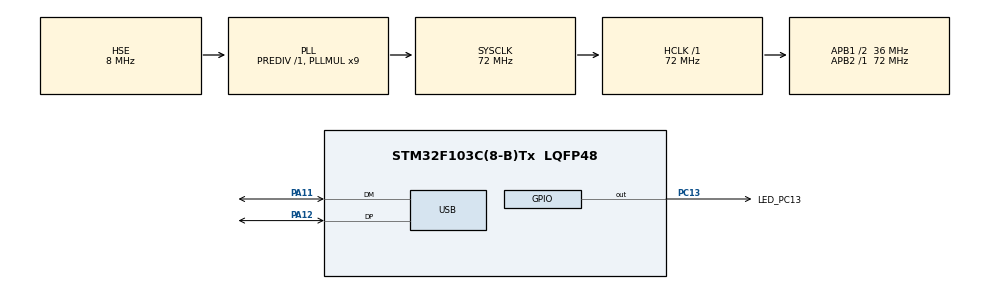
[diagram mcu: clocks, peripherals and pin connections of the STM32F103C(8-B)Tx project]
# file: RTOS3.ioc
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FREERTOS.BinarySemaphores01=myBinarySem01,Dynamic,NULL,Available
FREERTOS.Queues01=myQueue01,16,uint16_t,0,Dynamic,NULL,NULL
FREERTOS.Tasks01=defaultTask,0,128,StartDefaultTask,Default,NULL,Dynamic,NULL,NULL;LEDTask,-2,128,LEDFun,Default,NULL,Dynamic,NULL,NULL;USBFTask,-2,128,USBFun,Default,NULL,Dynamic,NULL,NULL
Mcu.Family=STM32F1
Mcu.Name=STM32F103C(8-B)Tx
Mcu.Package=LQFP48
NVIC.PriorityGroup=NVIC_PRIORITYGROUP_4
NVIC.TIM4_IRQn=true\:15\:0\:false\:false\:true\:false\:false\:true\:true
NVIC.TimeBase=TIM4_IRQn
NVIC.TimeBaseIP=TIM4
NVIC.USB_LP_CAN1_RX0_IRQn=true\:5\:0\:false\:false\:true\:true\:true\:true\:true
PA11.Mode=Device
PA11.Signal=USB_DM
PA12.Mode=Device
PA12.Signal=USB_DP
PA13.Mode=Serial_Wire
PA13.Signal=SYS_JTMS-SWDIO
PA14.Mode=Serial_Wire
PA14.Signal=SYS_JTCK-SWCLK
PC13-TAMPER-RTC.GPIO_Label=LED_PC13
PC13-TAMPER-RTC.GPIO_ModeDefaultOutputPP=GPIO_MODE_OUTPUT_OD
PC13-TAMPER-RTC.GPIO_PuPd=GPIO_PULLUP
PC13-TAMPER-RTC.Signal=GPIO_Output
PC14-OSC32_IN.Mode=LSE-External-Oscillator
PC14-OSC32_IN.Signal=RCC_OSC32_IN
PC15-OSC32_OUT.Mode=LSE-External-Oscillator
PC15-OSC32_OUT.Signal=RCC_OSC32_OUT
PD0-OSC_IN.Mode=HSE-External-Oscillator
PD0-OSC_IN.Signal=RCC_OSC_IN
PD1-OSC_OUT.Mode=HSE-External-Oscillator
PD1-OSC_OUT.Signal=RCC_OSC_OUT
ProjectManager.HeapSize=0x200
ProjectManager.StackSize=0x400
ProjectManager.TargetToolchain=CMake
RCC.AHBFreq_Value=72000000
RCC.APB1CLKDivider=RCC_HCLK_DIV2
RCC.APB1Freq_Value=36000000
RCC.APB1TimFreq_Value=72000000
RCC.APB2Freq_Value=72000000
RCC.APB2TimFreq_Value=72000000
RCC.HCLKFreq_Value=72000000
RCC.PLLMUL=RCC_PLL_MUL9
RCC.SYSCLKFreq_VALUE=72000000
RCC.SYSCLKSource=RCC_SYSCLKSOURCE_PLLCLK
RCC.USBFreq_Value=48000000
RCC.USBPrescaler=RCC_USBCLKSOURCE_PLL_DIV1_5
USB_DEVICE.CLASS_NAME_FS=CDC
USB_DEVICE.VirtualMode=Cdc
USB_DEVICE.VirtualModeFS=Cdc_FS
VP_FREERTOS_VS_CMSIS_V1.Mode=CMSIS_V1
VP_SYS_VS_tim4.Mode=TIM4
VP_USB_DEVICE_VS_USB_DEVICE_CDC_FS.Mode=CDC_FS
board=custom

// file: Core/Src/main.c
/* USER CODE BEGIN Header */
/**
  ******************************************************************************
  * @file           : main.c
  * @brief          : Main program body
  ******************************************************************************
  * @attention
  *
  * Copyright (c) 2025 STMicroelectronics.
  * All rights reserved.
  *
  * This software is licensed under terms that can be found in the LICENSE file
  * in the root directory of this software component.
  * If no LICENSE file comes with this software, it is provided AS-IS.
  *
  ******************************************************************************
  */
/* USER CODE END Header */
#include "main.h"
#include "cmsis_os.h"
#include "usb_device.h"
#include "gpio.h"

void SystemClock_Config(void);
void MX_FREERTOS_Init(void);

int main(void)
{

  /* MCU Configuration--------------------------------------------------------*/

  /* Reset of all peripherals, Initializes the Flash interface and the Systick. */
  HAL_Init();

  /* Configure the system clock */
  SystemClock_Config();

  /* Initialize all configured peripherals */
  MX_GPIO_Init();

  /* Call init function for freertos objects (in cmsis_os2.c) */
  MX_FREERTOS_Init();

  /* Start scheduler */
  osKernelStart();

  /* We should never get here as control is now taken by the scheduler */

  /* Infinite loop */
  while (1)
  {

  }
}

void SystemClock_Config(void)
{
  RCC_OscInitTypeDef RCC_OscInitStruct = {0};
  RCC_ClkInitTypeDef RCC_ClkInitStruct = {0};
  RCC_PeriphCLKInitTypeDef PeriphClkInit = {0};

  /** Initializes the RCC Oscillators according to the specified parameters
  * in the RCC_OscInitTypeDef structure.
  */
  RCC_OscInitStruct.OscillatorType = RCC_OSCILLATORTYPE_HSE;
  RCC_OscInitStruct.HSEState = RCC_HSE_ON;
  RCC_OscInitStruct.HSEPredivValue = RCC_HSE_PREDIV_DIV1;
  RCC_OscInitStruct.HSIState = RCC_HSI_ON;
  RCC_OscInitStruct.PLL.PLLState = RCC_PLL_ON;
  RCC_OscInitStruct.PLL.PLLSource = RCC_PLLSOURCE_HSE;
  RCC_OscInitStruct.PLL.PLLMUL = RCC_PLL_MUL9;
  if (HAL_RCC_OscConfig(&RCC_OscInitStruct) != HAL_OK)
  {
    Error_Handler();
  }

  /** Initializes the CPU, AHB and APB buses clocks
  */
  RCC_ClkInitStruct.ClockType = RCC_CLOCKTYPE_HCLK|RCC_CLOCKTYPE_SYSCLK
                              |RCC_CLOCKTYPE_PCLK1|RCC_CLOCKTYPE_PCLK2;
  RCC_ClkInitStruct.SYSCLKSource = RCC_SYSCLKSOURCE_PLLCLK;
  RCC_ClkInitStruct.AHBCLKDivider = RCC_SYSCLK_DIV1;
  RCC_ClkInitStruct.APB1CLKDivider = RCC_HCLK_DIV2;
  RCC_ClkInitStruct.APB2CLKDivider = RCC_HCLK_DIV1;

  if (HAL_RCC_ClockConfig(&RCC_ClkInitStruct, FLASH_LATENCY_2) != HAL_OK)
  {
    Error_Handler();
  }
  PeriphClkInit.PeriphClockSelection = RCC_PERIPHCLK_USB;
  PeriphClkInit.UsbClockSelection = RCC_USBCLKSOURCE_PLL_DIV1_5;
  if (HAL_RCCEx_PeriphCLKConfig(&PeriphClkInit) != HAL_OK)
  {
    Error_Handler();
  }
}

void HAL_TIM_PeriodElapsedCallback(TIM_HandleTypeDef *htim)
{
  if (htim->Instance == TIM4)
  {
    HAL_IncTick();
  }
}

void Error_Handler(void)
{
  __disable_irq();
  while (1)
  {
  }
}

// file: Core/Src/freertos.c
/* USER CODE BEGIN Header */
/**
  ******************************************************************************
  * File Name          : freertos.c
  * Description        : Code for freertos applications
  ******************************************************************************
  * @attention
  *
  * Copyright (c) 2025 STMicroelectronics.
  * All rights reserved.
  *
  * This software is licensed under terms that can be found in the LICENSE file
  * in the root directory of this software component.
  * If no LICENSE file comes with this software, it is provided AS-IS.
  *
  ******************************************************************************
  */
/* USER CODE END Header */

#include "FreeRTOS.h"
#include "task.h"
#include "main.h"
#include "cmsis_os.h"

/* USER CODE BEGIN Includes */
#include "usbd_cdc_if.h"
#include <stdint.h>
#include <ctype.h>
/* USER CODE END Includes */

/* USER CODE BEGIN PTD */
extern QueueHandle_t messageQueue1;
extern QueueHandle_t messageQueue2;
SemaphoreHandle_t sem;

/* USER CODE END PTD */

/* USER CODE BEGIN PD */
int pase = 0;
/* USER CODE END PD */

/* USER CODE BEGIN Variables */
QueueHandle_t messageQueue3;

/* USER CODE END Variables */
osThreadId defaultTaskHandle;
osThreadId LEDTaskHandle;
osThreadId USBFTaskHandle;
osMessageQId myQueue01Handle;
osSemaphoreId myBinarySem01Handle;

void StartDefaultTask(void const * argument);
void LEDFun(void const * argument);
void USBFun(void const * argument);

extern void MX_USB_DEVICE_Init(void);
void MX_FREERTOS_Init(void); /* (MISRA C 2004 rule 8.1) */

/* GetIdleTaskMemory prototype (linked to static allocation support) */
void vApplicationGetIdleTaskMemory( StaticTask_t **ppxIdleTaskTCBBuffer, StackType_t **ppxIdleTaskStackBuffer, uint32_t *pulIdleTaskStackSize );

/* USER CODE BEGIN GET_IDLE_TASK_MEMORY */
static StaticTask_t xIdleTaskTCBBuffer;
static StackType_t xIdleStack[configMINIMAL_STACK_SIZE];

void vApplicationGetIdleTaskMemory( StaticTask_t **ppxIdleTaskTCBBuffer, StackType_t **ppxIdleTaskStackBuffer, uint32_t *pulIdleTaskStackSize )
{
  *ppxIdleTaskTCBBuffer = &xIdleTaskTCBBuffer;
  *ppxIdleTaskStackBuffer = &xIdleStack[0];
  *pulIdleTaskStackSize = configMINIMAL_STACK_SIZE;
  /* place for user code */
}
/* USER CODE END GET_IDLE_TASK_MEMORY */

void MX_FREERTOS_Init(void) {

  /* Create the semaphores(s) */
  /* definition and creation of myBinarySem01 */
  osSemaphoreDef(myBinarySem01);
  myBinarySem01Handle = osSemaphoreCreate(osSemaphore(myBinarySem01), 1);

  /* Create the queue(s) */
  /* definition and creation of myQueue01 */
  osMessageQDef(myQueue01, 16, uint16_t);
  myQueue01Handle = osMessageCreate(osMessageQ(myQueue01), NULL);

  /* USER CODE BEGIN RTOS_QUEUES */
  /* add queues, ... */
  messageQueue1 = xQueueCreate(20, sizeof(uint8_t)); // 创建大小为10的消息队列
  messageQueue2 = xQueueCreate(20, sizeof(uint32_t)); // 创建大小为10的消息队列
  messageQueue3 = xQueueCreate(10, sizeof(int)); // 创建大小为10的消息队列

  sem = xSemaphoreCreateBinary();
  xSemaphoreGive(sem); // 初始化信号量
  /* USER CODE END RTOS_QUEUES */

  /* Create the thread(s) */
  /* definition and creation of defaultTask */
  osThreadDef(defaultTask, StartDefaultTask, osPriorityNormal, 0, 128);
  defaultTaskHandle = osThreadCreate(osThread(defaultTask), NULL);

  /* definition and creation of LEDTask */
  osThreadDef(LEDTask, LEDFun, osPriorityLow, 0, 128);
  LEDTaskHandle = osThreadCreate(osThread(LEDTask), NULL);

  /* definition and creation of USBFTask */
  osThreadDef(USBFTask, USBFun, osPriorityLow, 0, 128);
  USBFTaskHandle = osThreadCreate(osThread(USBFTask), NULL);

  /* USER CODE BEGIN RTOS_THREADS */
  /* add threads, ... */
  vTaskStartScheduler();

  /* USER CODE END RTOS_THREADS */

}

void StartDefaultTask(void const * argument)
{
  /* init code for USB_DEVICE */
  MX_USB_DEVICE_Init();
  for(;;)
  {
    osDelay(1);
  }
}

void LEDFun(void const * argument)
{
  /* USER CODE BEGIN LEDFun */
  /* Infinite loop */
  for(;;)
  {
    int data = 500;
    xQueueReceive(messageQueue3, &data, 0);
    HAL_GPIO_TogglePin(LED_PC13_GPIO_Port, LED_PC13_Pin);
    HAL_Delay(data);
    uint8_t rx_buf[64];  // 接收缓冲区
    uint32_t len = 0;

    if(CDC_Receive_FS(rx_buf, &len) == USBD_OK && len > 0) {
      // 有数据到达，len是接收到的字节数
    }

  }
  osDelay(10 );
  /* USER CODE END LEDFun */
}

void USBFun(void const * argument)
{
  /* USER CODE BEGIN USBFun */
  /* Infinite loop */
  for(;;)
  {
    uint8_t* data = NULL;
    uint32_t len = 0;

    // 使用 portMAX_DELAY 阻塞等待，避免忙等待
    if(xQueueReceive(messageQueue1, &data, portMAX_DELAY) == pdTRUE &&
       xQueueReceive(messageQueue2, &len, portMAX_DELAY) == pdTRUE)
    {
      if(data && len > 0)
      {
        uint16_t result = 0;
        for (uint32_t i = 0; i < len; i++) {
          if (isdigit(data[i])) {
            result = result * 10 + (data[i] - '0');
          }
        }
        xQueueSend(messageQueue3, &result, 0);

        // 释放动态内存
        vPortFree(data);
      }
    }
  }
  /* USER CODE END USBFun */
}
